# MDR1986VK01 register map
File version: 1.0.2
Registers are 32-bit, read-write, no defined reset value unless marked. A register's access mark holds for its fields unless they carry their own. Offsets are from the block's base; [hi:lo] are bit positions; {n}, {i} and the like mark numbered series; 'fields as' and 'values as' point back to an identical list.

## MDR_CLK — MDR_CLK description
Base 0x40000000
0x00 KEY — KEY description
0x04 MAX_CLK — MAX_CLK description
  [3:0] SELECT — SELECT description
    0=HSI (HSI selected); 1=HSI/2 (HSI/2 selected); 2=HSE0 (HSE0 selected); 3=HSE0/2 (HSE0/2 selected); 4=HSE1 (HSE1 selected); 5=HSE1/2 (HSE1/2 selected); 6=LSI (LSI selected); 7=LSE (LSE selected); {v}=PLL{v-8} (PLL{v-8} selected) (v=8..11)
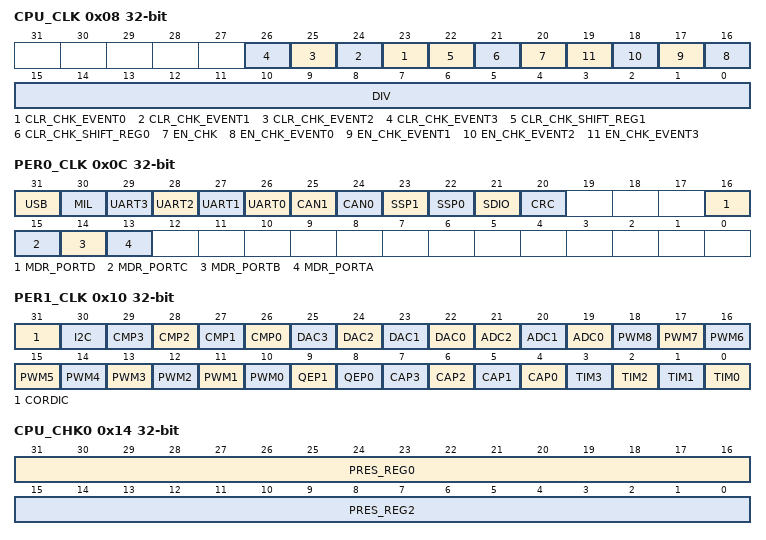
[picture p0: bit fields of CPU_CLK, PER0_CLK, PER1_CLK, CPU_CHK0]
0x08 CPU_CLK — CPU_CLK description
  [n+23] CLR_CHK_EVENT{n} (n=0..3) — CLR_CHK_EVENT{n} description
  [22] CLR_CHK_SHIFT_REG1 — CLR_CHK_SHIFT_REG1 description
  [21] CLR_CHK_SHIFT_REG0 — CLR_CHK_SHIFT_REG0 description
  [20] EN_CHK — EN_CHK description
  [n+16] EN_CHK_EVENT{n} (n=0..3) — EN_CHK_EVENT{n} description
  [15:0] DIV — DIV description
0x0C PER0_CLK — PER0_CLK description
  [31] USB — USB description
  [30] MIL — MIL description
  [n+26] UART{n} (n=0..3) — UART{n} description
  [25] CAN1 — CAN1 description
  [24] CAN0 — CAN0 description
  [23] SSP1 — SSP1 description
  [22] SSP0 — SSP0 description
  [21] SDIO — SDIO description
  [20] CRC — CRC description
  [16] MDR_PORTD — MDR_PORTD description
  [15] MDR_PORTC — MDR_PORTC description
  [14] MDR_PORTB — MDR_PORTB description
  [13] MDR_PORTA — MDR_PORTA description
0x10 PER1_CLK — PER1_CLK description
  [31] CORDIC — CORDIC description
  [30] I2C — I2C description
  [n+26] CMP{n} (n=0..3) — CMP{n} description
  [n+22] DAC{n} (n=0..3) — DAC{n} description
  [21] ADC2 — ADC2 description
  [20] ADC1 — ADC1 description
  [19] ADC0 — ADC0 description
  [n+10] PWM{n} (n=0..8) — PWM{n} description
  [9] QEP1 — QEP1 description
  [8] QEP0 — QEP0 description
  [n+4] CAP{n} (n=0..3) — CAP{n} description
  [n] TIM{n} (n=0..3) — TIM{n} description
0x14 CPU_CHK0 — CPU_CHK0 description
  [31:16] PRES_REG0 — PRES_REG0 description
  [15:0] PRES_REG2 — PRES_REG2 description
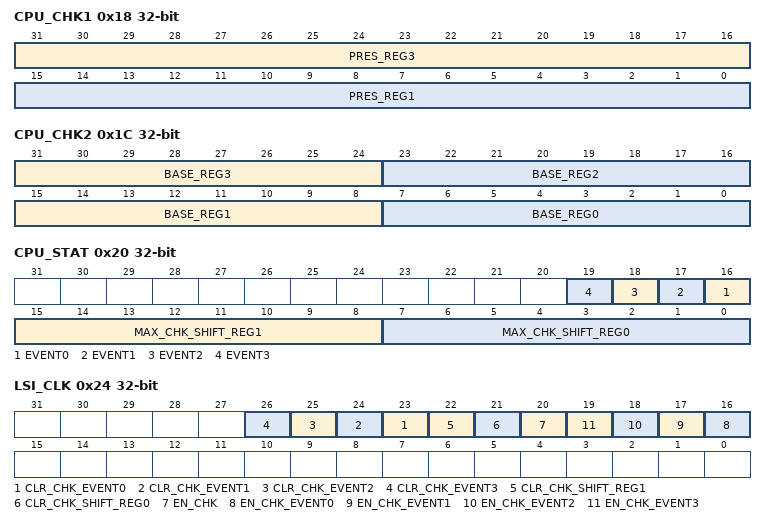
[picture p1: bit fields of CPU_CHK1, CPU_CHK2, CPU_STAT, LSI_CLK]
0x18 CPU_CHK1 — CPU_CHK1 description
  [31:16] PRES_REG3 — PRES_REG3 description
  [15:0] PRES_REG1 — PRES_REG1 description
0x1C CPU_CHK2 — CPU_CHK2 description
  [31:24] BASE_REG3 — BASE_REG0 description
  [23:16] BASE_REG2 — BASE_REG0 description
  [15:8] BASE_REG1 — BASE_REG1 description
  [7:0] BASE_REG0 — BASE_REG0 description
0x20 CPU_STAT — CPU_STAT description
  [n+16] EVENT{n} (n=0..3) — EVENT{n} description
  [15:8] MAX_CHK_SHIFT_REG1 ro — MAX_CHK_SHIFT_REG1 description
  [7:0] MAX_CHK_SHIFT_REG0 ro — MAX_CHK_SHIFT_REG0 description
0x24 LSI_CLK — LSI_CLK description
  [n+23] CLR_CHK_EVENT{n} (n=0..3) — CLR_CHK_EVENT{n} description
  [22] CLR_CHK_SHIFT_REG1 — CLR_CHK_SHIFT_REG1 description
  [21] CLR_CHK_SHIFT_REG0 — CLR_CHK_SHIFT_REG0 description
  [20] EN_CHK — EN_CHK description
  [n+16] EN_CHK_EVENT{n} (n=0..3) — EN_CHK_EVENT{n} description
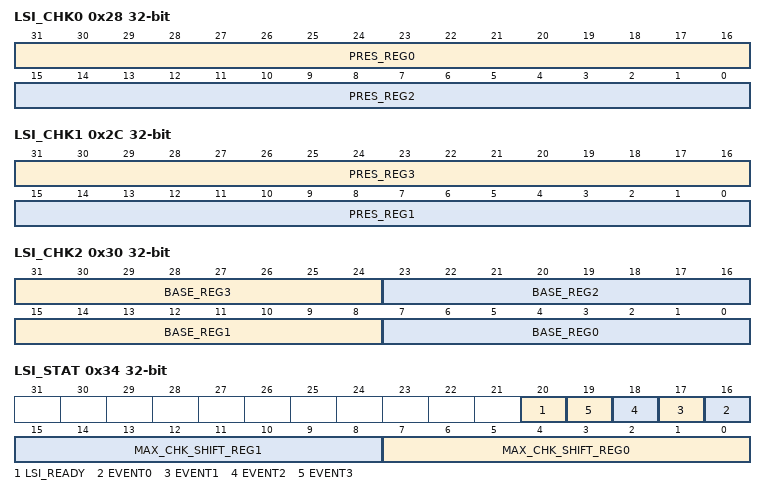
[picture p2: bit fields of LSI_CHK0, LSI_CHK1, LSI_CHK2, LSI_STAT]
0x28 LSI_CHK0 — LSI_CHK0 description
  fields as CPU_CHK0
0x2C LSI_CHK1 — LSI_CHK1 description
  fields as CPU_CHK1
0x30 LSI_CHK2 — LSI_CHK2 description
  fields as CPU_CHK2
0x34 LSI_STAT — LSI_STAT description
  [20] LSI_READY — LSI_READY description
  [n+16] EVENT{n} (n=0..3) — EVENT{n} description
  [15:8] MAX_CHK_SHIFT_REG1 ro — MAX_CHK_SHIFT_REG1 description
  [7:0] MAX_CHK_SHIFT_REG0 ro — MAX_CHK_SHIFT_REG0 description
0x38 HSI_STAT — HSI_STAT description
  [20] HSI_READY — HSI_READY description
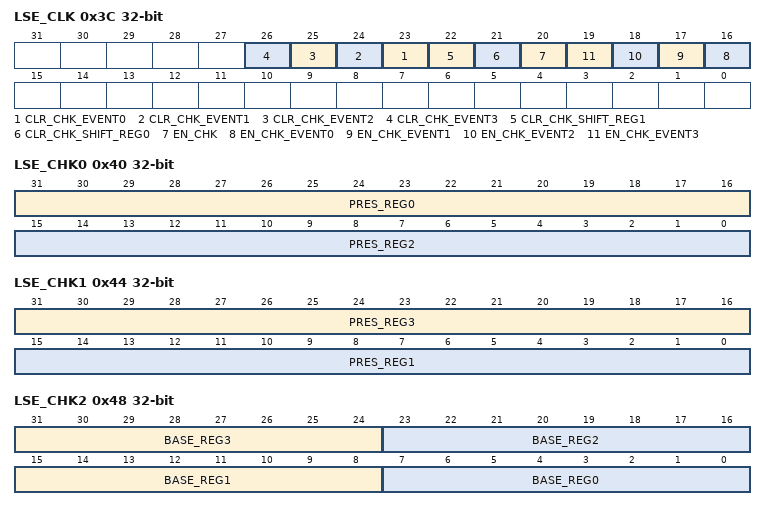
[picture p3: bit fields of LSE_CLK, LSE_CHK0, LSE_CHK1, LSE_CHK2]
0x3C LSE_CLK — LSE_CLK description
  fields as LSI_CLK
0x40 LSE_CHK0 — LSE_CHK0 description
  fields as CPU_CHK0
0x44 LSE_CHK1 — LSE_CHK1 description
  fields as CPU_CHK1
0x48 LSE_CHK2 — LSE_CHK2 description
  fields as CPU_CHK2
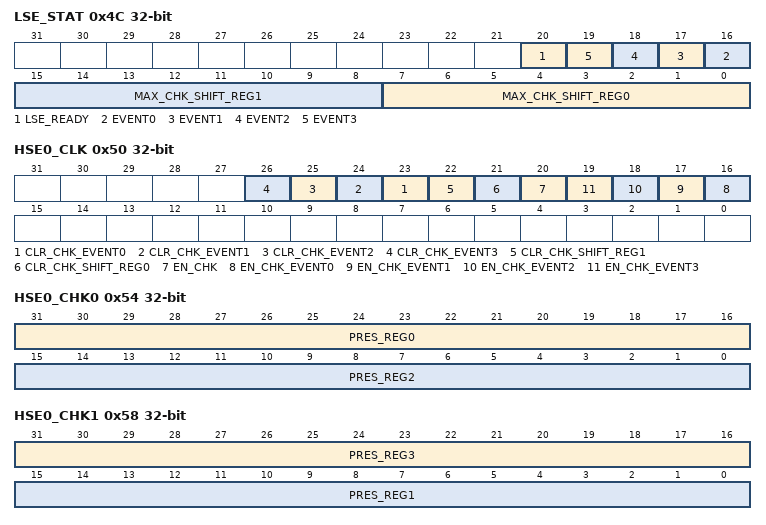
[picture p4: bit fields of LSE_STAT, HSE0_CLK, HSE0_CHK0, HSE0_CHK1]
0x4C LSE_STAT — LSE_STAT description
  [20] LSE_READY — LSE_READY description
  [n+16] EVENT{n} (n=0..3) — EVENT{n} description
  [15:8] MAX_CHK_SHIFT_REG1 ro — MAX_CHK_SHIFT_REG1 description
  [7:0] MAX_CHK_SHIFT_REG0 ro — MAX_CHK_SHIFT_REG0 description
0x50 HSE0_CLK — HSE0_CLK description
  fields as LSI_CLK
0x54 HSE0_CHK0 — HSE0_CHK0 description
  fields as CPU_CHK0
0x58 HSE0_CHK1 — HSE0_CHK1 description
  fields as CPU_CHK1
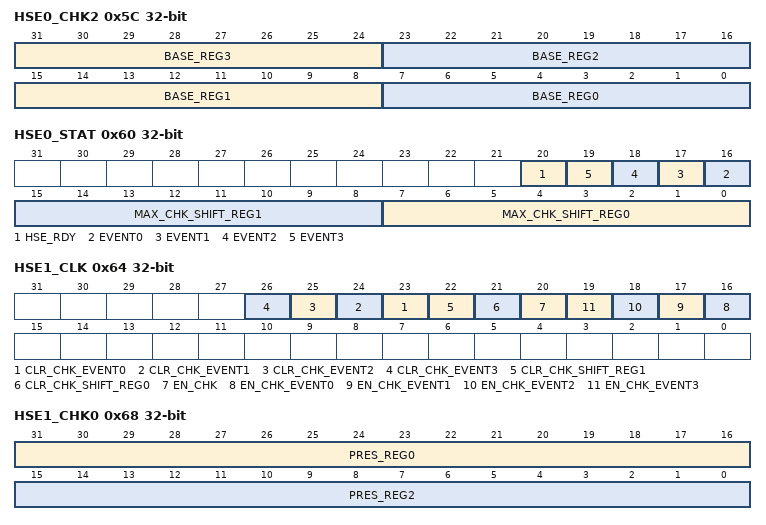
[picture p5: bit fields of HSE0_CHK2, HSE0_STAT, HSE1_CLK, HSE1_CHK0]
0x5C HSE0_CHK2 — HSE0_CHK2 description
  fields as CPU_CHK2
0x60 HSE0_STAT — HSE0_STAT description
  [20] HSE_RDY — HSE_RDY description
  [n+16] EVENT{n} (n=0..3) — EVENT{n} description
  [15:8] MAX_CHK_SHIFT_REG1 ro — MAX_CHK_SHIFT_REG1 description
  [7:0] MAX_CHK_SHIFT_REG0 ro — MAX_CHK_SHIFT_REG0 description
0x64 HSE1_CLK — HSE1_CLK description
  fields as LSI_CLK
0x68 HSE1_CHK0 — HSE1_CHK0 description
  fields as CPU_CHK0
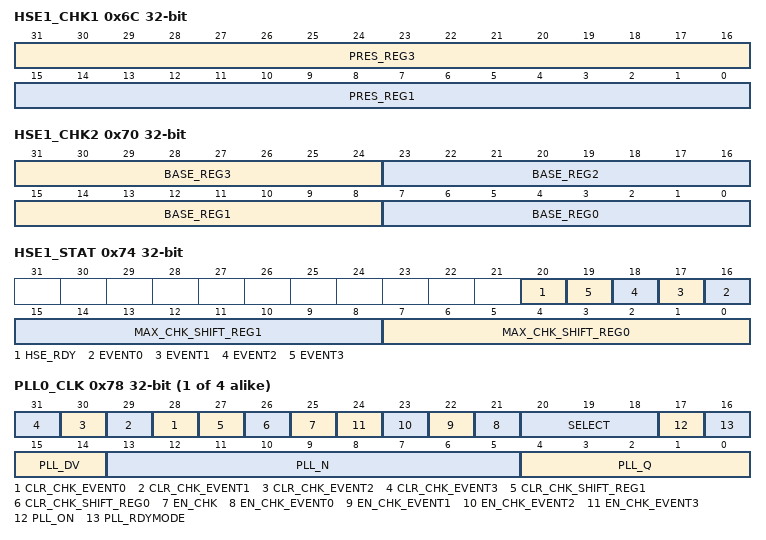
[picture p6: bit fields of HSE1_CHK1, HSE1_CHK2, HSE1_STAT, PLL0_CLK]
0x6C HSE1_CHK1 — HSE1_CHK1 description
  fields as CPU_CHK1
0x70 HSE1_CHK2 — HSE1_CHK2 description
  fields as CPU_CHK2
0x74 HSE1_STAT — HSE1_STAT description
  fields as HSE0_STAT
{0x78+0x14*i} PLL{i}_CLK (i=0..3) — PLL{i}_CLK description
  [n+28] CLR_CHK_EVENT{n} (n=0..3) — CLR_CHK_EVENT{n} description
  [27] CLR_CHK_SHIFT_REG1 — CLR_CHK_SHIFT_REG1 description
  [26] CLR_CHK_SHIFT_REG0 — CLR_CHK_SHIFT_REG0 description
  [25] EN_CHK — EN_CHK description
  [n+21] EN_CHK_EVENT{n} (n=0..3) — EN_CHK_EVENT{n} description
  [20:18] SELECT — SELECT description
    0=HSI (HSI is PLL source); 1=HSI/2 (HSI/2 is PLL source); 2=HSE0 (HSE0 is PLL source); 3=HSE0/2 (HSE0/2 is PLL source); 4=HSE1 (HSE1 is PLL source); 5=HSE1/2 (HSE1/2 is PLL source)
  [17] PLL_ON — PLL_ON description
  [16] PLL_RDYMODE — PLL_RDYMODE description
  [15:14] PLL_DV — PLL_DV description
    0=Div1 (FOUT = FINT); 1=Div2 (FOUT = FINT/2); 2=Div4 (FOUT = FINT/4)
  [13:5] PLL_N — PLL_N description
  [4:0] PLL_Q — PLL_Q description
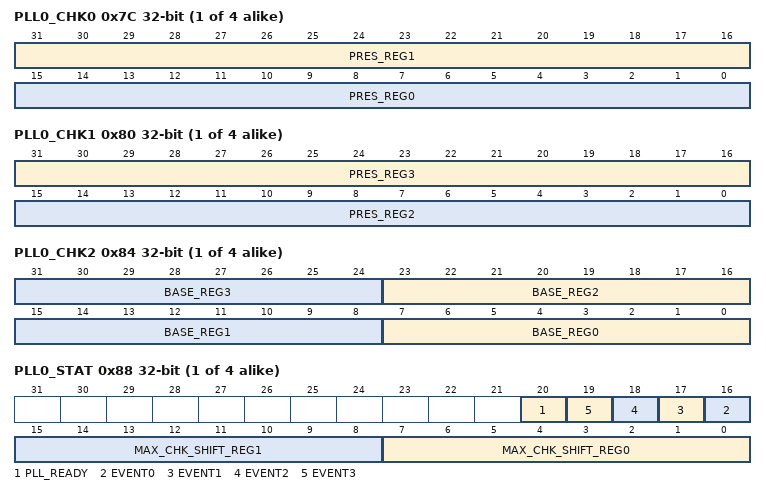
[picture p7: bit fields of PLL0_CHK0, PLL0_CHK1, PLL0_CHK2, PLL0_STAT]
{0x7C+0x14*i} PLL{i}_CHK0 (i=0..3) — PLL{i}_CHK0 description
  [31:16] PRES_REG1 — PRES_REG1 description
  [15:0] PRES_REG0 — PRES_REG0 description
{0x80+0x14*i} PLL{i}_CHK1 (i=0..3) — PLL{i}_CHK1 description
  [31:16] PRES_REG3 — PRES_REG3 description
  [15:0] PRES_REG2 — PRES_REG2 description
{0x84+0x14*i} PLL{i}_CHK2 (i=0..3) — PLL{i}_CHK2 description
  [8n+7:8n] BASE_REG{n} (n=0..3) — BASE_REG{n} description
{0x88+0x14*i} PLL{i}_STAT (i=0..3) — PLL{i}_STAT description
  [20] PLL_READY — PLL_READY description
  [n+16] EVENT{n} (n=0..3) — EVENT{n} description
  [15:8] MAX_CHK_SHIFT_REG1 ro — MAX_CHK_SHIFT_REG1 description
  [7:0] MAX_CHK_SHIFT_REG0 ro — MAX_CHK_SHIFT_REG0 description
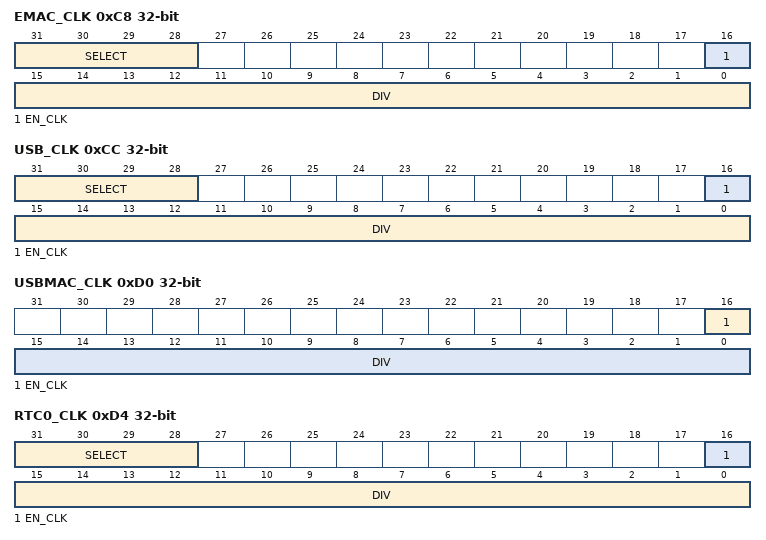
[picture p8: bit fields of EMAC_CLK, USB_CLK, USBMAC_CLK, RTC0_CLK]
0xC8 EMAC_CLK — EMAC_CLK description
  [31:28] SELECT — SELECT description
    0=HSI (HSI selected); 1=HSE0 (HSE0 selected); 2=HSE1 (HSE1 selected); 3=LSI (LSI selected); 4=LSE (LSE selected); {v}=PLL{v-5} (PLL{v-5} selected) (v=5..8); 13=MAX_CLK (MAX_CLK selected)
  [16] EN_CLK — EN_CLK description
  [15:0] DIV — DIV description
0xCC USB_CLK — USB_CLK description
  fields as EMAC_CLK
0xD0 USBMAC_CLK — USBMAC_CLK description
  [16] EN_CLK — EN_CLK description
  [15:0] DIV — DIV description
0xD4 RTC0_CLK — RTC0_CLK description
  fields as EMAC_CLK
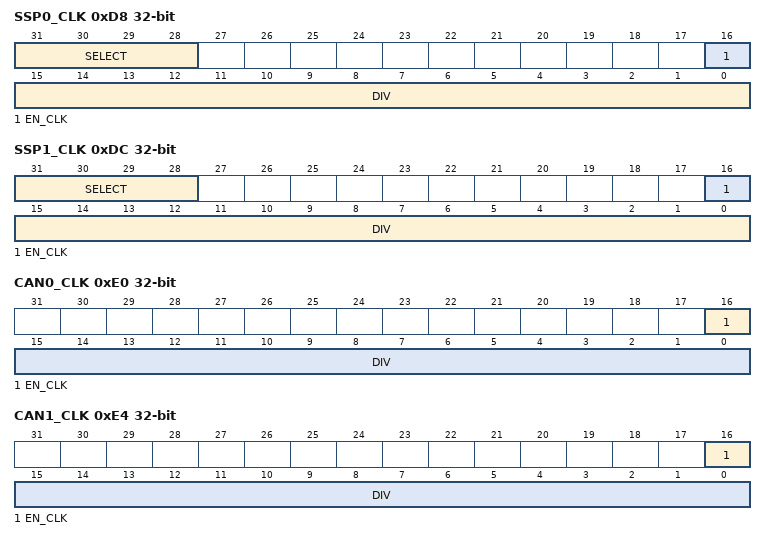
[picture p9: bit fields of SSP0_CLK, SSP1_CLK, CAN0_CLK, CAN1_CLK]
0xD8 SSP0_CLK — SSP0_CLK description
  fields as EMAC_CLK
0xDC SSP1_CLK — SSP1_CLK description
  fields as EMAC_CLK
0xE0 CAN0_CLK — CAN0_CLK description
  [16] EN_CLK — EN_CLK description
  [15:0] DIV — DIV description
0xE4 CAN1_CLK — CAN1_CLK description
  [16] EN_CLK — EN_CLK description
  [15:0] DIV — DIV description
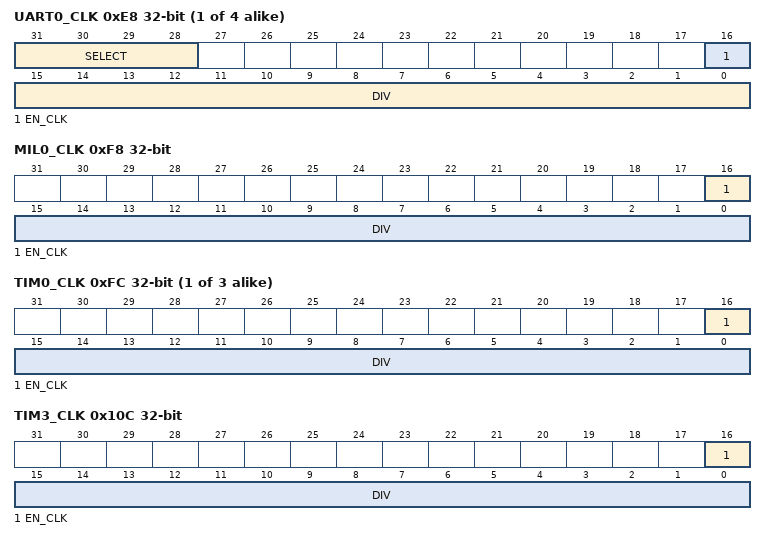
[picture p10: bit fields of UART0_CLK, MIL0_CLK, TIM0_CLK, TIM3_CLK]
{0xE8+4i} UART{i}_CLK (i=0..3) — UART{i}_CLK description
  fields as EMAC_CLK
0xF8 MIL0_CLK — MIL0_CLK description
  [16] EN_CLK — EN_CLK description
  [15:0] DIV — DIV description
{0xFC+4i} TIM{i}_CLK (i=0..2) — TIM{i}_CLK description
  [16] EN_CLK — EN_CLK description
  [15:0] DIV — DIV description
0x10C TIM3_CLK — TIM3_CLK description
  [16] EN_CLK — EN_CLK description
  [15:0] DIV — DIV description
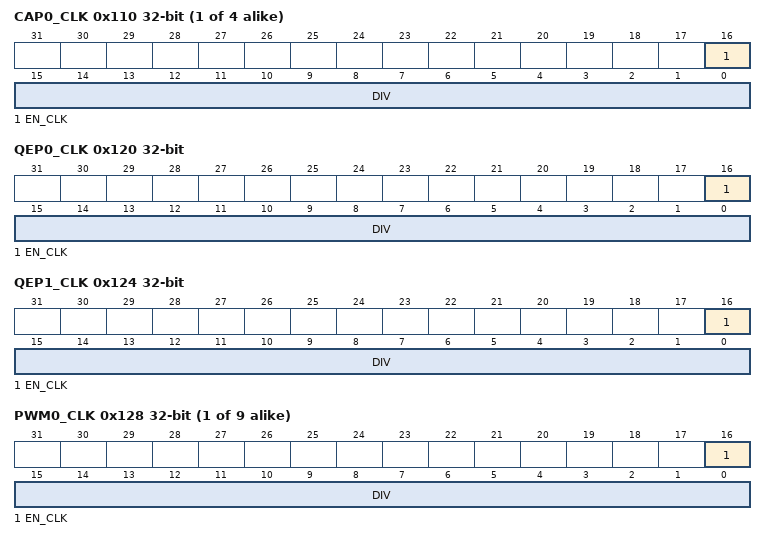
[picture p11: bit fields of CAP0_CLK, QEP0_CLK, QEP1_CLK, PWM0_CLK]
{0x110+4i} CAP{i}_CLK (i=0..3) — CAP{i}_CLK description
  [16] EN_CLK — EN_CLK description
  [15:0] DIV — DIV description
0x120 QEP0_CLK — QEP0_CLK description
  [16] EN_CLK — EN_CLK description
  [15:0] DIV — DIV description
0x124 QEP1_CLK — QEP1_CLK description
  [16] EN_CLK — EN_CLK description
  [15:0] DIV — DIV description
{0x128+4i} PWM{i}_CLK (i=0..8) — PWM{i}_CLK description
  [16] EN_CLK — EN_CLK description
  [15:0] DIV — DIV description
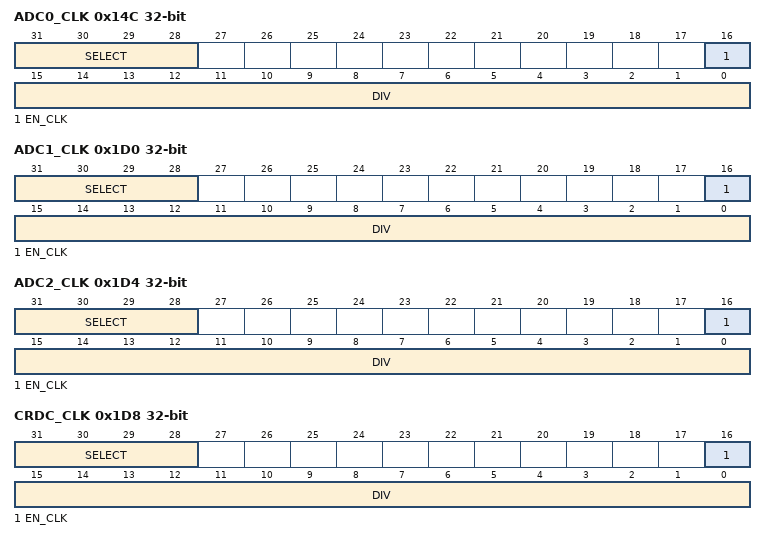
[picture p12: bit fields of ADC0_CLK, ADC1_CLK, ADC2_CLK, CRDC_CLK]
0x14C ADC0_CLK — ADC0_CLK description
  fields as EMAC_CLK
0x1D0 ADC1_CLK — ADC1_CLK description
  fields as EMAC_CLK
0x1D4 ADC2_CLK — ADC2_CLK description
  fields as EMAC_CLK
0x1D8 CRDC_CLK — CRDC_CLK description
  fields as EMAC_CLK
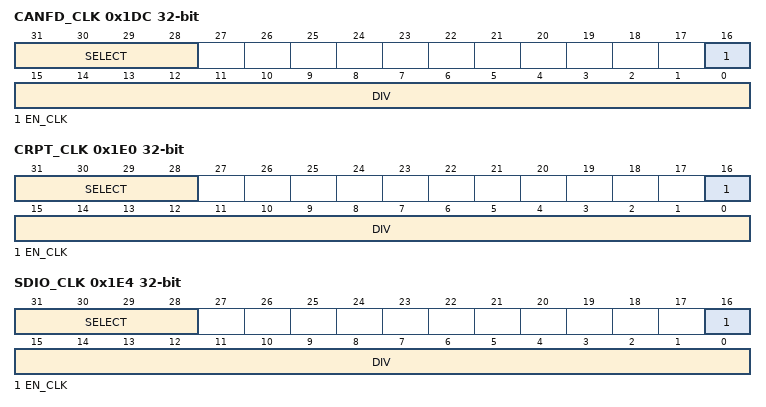
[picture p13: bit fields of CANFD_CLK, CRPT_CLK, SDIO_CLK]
0x1DC CANFD_CLK — CANFD_CLK description
  fields as EMAC_CLK
0x1E0 CRPT_CLK — CRPT_CLK description
  fields as EMAC_CLK
0x1E4 SDIO_CLK — SDIO_CLK description
  fields as EMAC_CLK
